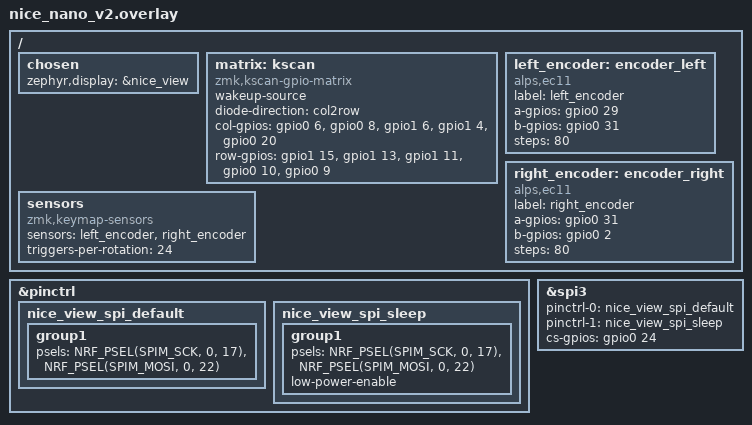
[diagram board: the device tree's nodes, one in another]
#include <physical_layouts.dtsi>

&pinctrl {
	nice_view_spi_default: nice_view_spi_default {
        group1 {
            psels = <NRF_PSEL(SPIM_SCK, 0, 17)>,   /* SCK pin */
                    <NRF_PSEL(SPIM_MOSI, 0, 22)>;  /* MOSI pin */
        };
    };

	nice_view_spi_sleep: nice_view_spi_sleep {
        group1 {
            psels = <NRF_PSEL(SPIM_SCK, 0, 17)>,
                    <NRF_PSEL(SPIM_MOSI, 0, 22)>;
            low-power-enable;
        };
    };
};

nice_view_spi: &spi3 {
    status = "okay";
    pinctrl-0 = <&nice_view_spi_default>;
    pinctrl-1 = <&nice_view_spi_sleep>;
    pinctrl-names = "default", "sleep";

    /* CS pin for the display */
    cs-gpios = <&gpio0 24 GPIO_ACTIVE_HIGH>;
};
	
/ {
	chosen {
		zephyr,display = &nice_view;
	};

	matrix: kscan {
		compatible = "zmk,kscan-gpio-matrix";
		wakeup-source;
		diode-direction = "col2row";

		col-gpios = 
			<&gpio0 6 GPIO_ACTIVE_HIGH>,
			<&gpio0 8 GPIO_ACTIVE_HIGH>,
			<&gpio1 6 GPIO_ACTIVE_HIGH>,
			<&gpio1 4 GPIO_ACTIVE_HIGH>,
			<&gpio0 20 GPIO_ACTIVE_HIGH>;

		row-gpios =
			<&gpio1 15 (GPIO_ACTIVE_HIGH | GPIO_PULL_DOWN)>,
			<&gpio1 13 (GPIO_ACTIVE_HIGH | GPIO_PULL_DOWN)>,
			<&gpio1 11 (GPIO_ACTIVE_HIGH | GPIO_PULL_DOWN)>,
			<&gpio0 10 (GPIO_ACTIVE_HIGH | GPIO_PULL_DOWN)>,
			<&gpio0 9 (GPIO_ACTIVE_HIGH | GPIO_PULL_DOWN)>;
	};

	left_encoder: encoder_left {
		compatible = "alps,ec11";
		label = "left_encoder";
		a-gpios = <&gpio0 29 (GPIO_ACTIVE_HIGH | GPIO_PULL_UP)>;
		b-gpios = <&gpio0 31 (GPIO_ACTIVE_HIGH | GPIO_PULL_UP)>;
		steps = <80>;
		status = "okay";
	};

	right_encoder: encoder_right {
		compatible = "alps,ec11";
		label = "right_encoder";
		a-gpios = <&gpio0 31 (GPIO_ACTIVE_HIGH | GPIO_PULL_UP)>;
		b-gpios = <&gpio0 2 (GPIO_ACTIVE_HIGH | GPIO_PULL_UP)>;
		steps = <80>;
		status = "okay";
	};

	sensors {
		compatible = "zmk,keymap-sensors";
		sensors = <&left_encoder &right_encoder>;
		triggers-per-rotation = <24>;
	};
};
